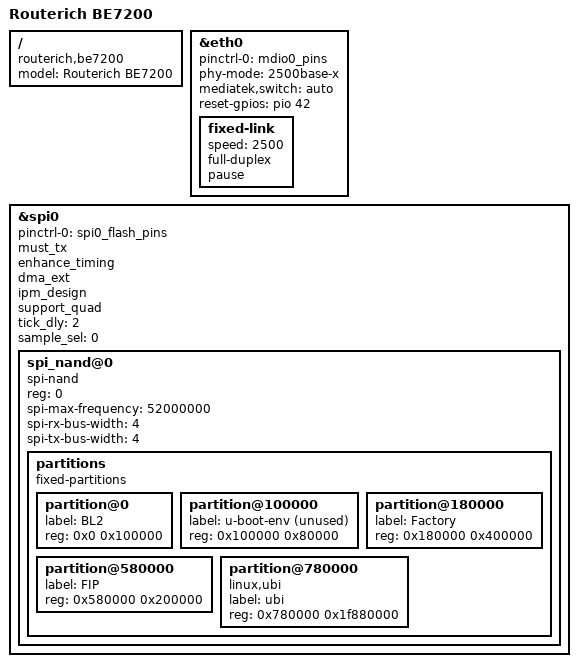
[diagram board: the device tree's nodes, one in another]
// SPDX-License-Identifier: GPL-2.0
/*
 * Copyright (c) 2025
 * Author: Mikhail Zhilkin <csharper2005@gmail.com>
 */

#include "mt7987a-u-boot.dtsi"
#include "mt7987-netsys-u-boot.dtsi"

/ {
	model = "Routerich BE7200";
	compatible = "routerich,be7200",
		     "mediatek,mt7987";
};

&eth0 {
	status = "okay";
	pinctrl-names = "default";
	pinctrl-0 = <&mdio0_pins>;
	phy-mode = "2500base-x";
	mediatek,switch = "auto";
	reset-gpios = <&pio 42 GPIO_ACTIVE_HIGH>;

	fixed-link {
		speed = <2500>;
		full-duplex;
		pause;
	};
};

&spi0 {
	pinctrl-names = "default";
	pinctrl-0 = <&spi0_flash_pins>;
	#address-cells = <1>;
	#size-cells = <0>;
	status = "okay";
	must_tx;
	enhance_timing;
	dma_ext;
	ipm_design;
	support_quad;
	tick_dly = <2>;
	sample_sel = <0>;

	spi_nand@0 {
		compatible = "spi-nand";
		reg = <0>;
		spi-max-frequency = <52000000>;
		spi-rx-bus-width = <4>;
		spi-tx-bus-width = <4>;

		partitions {
			compatible = "fixed-partitions";
			#address-cells = <1>;
			#size-cells = <1>;

			partition@0 {
				label = "BL2";
				reg = <0x0 0x100000>;
			};

			partition@100000 {
				label = "u-boot-env (unused)";
				reg = <0x100000 0x80000>;
			};

			partition@180000 {
				label = "Factory";
				reg = <0x180000 0x400000>;
			};

			partition@580000 {
				label = "FIP";
				reg = <0x580000 0x200000>;
			};

			partition@780000 {
				label = "ubi";
				reg = <0x780000 0x1f880000>;
				compatible = "linux,ubi";
			};
		};
	};
};
